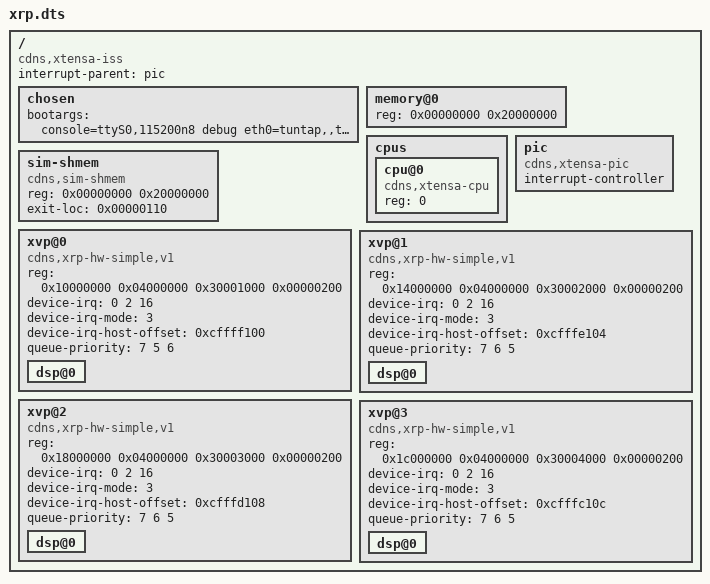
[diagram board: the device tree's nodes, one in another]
/*
 * Copyright (c) 2016 - 2019 Cadence Design Systems Inc.
 *
 * Permission is hereby granted, free of charge, to any person obtaining
 * a copy of this software and associated documentation files (the
 * "Software"), to deal in the Software without restriction, including
 * without limitation the rights to use, copy, modify, merge, publish,
 * distribute, sublicense, and/or sell copies of the Software, and to
 * permit persons to whom the Software is furnished to do so, subject to
 * the following conditions:
 *
 * The above copyright notice and this permission notice shall be included
 * in all copies or substantial portions of the Software.
 *
 * THE SOFTWARE IS PROVIDED "AS IS", WITHOUT WARRANTY OF ANY KIND,
 * EXPRESS OR IMPLIED, INCLUDING BUT NOT LIMITED TO THE WARRANTIES OF
 * MERCHANTABILITY, FITNESS FOR A PARTICULAR PURPOSE AND NONINFRINGEMENT.
 * IN NO EVENT SHALL THE AUTHORS OR COPYRIGHT HOLDERS BE LIABLE FOR ANY
 * CLAIM, DAMAGES OR OTHER LIABILITY, WHETHER IN AN ACTION OF CONTRACT,
 * TORT OR OTHERWISE, ARISING FROM, OUT OF OR IN CONNECTION WITH THE
 * SOFTWARE OR THE USE OR OTHER DEALINGS IN THE SOFTWARE.
 */

/dts-v1/;

/ {
	compatible = "cdns,xtensa-iss";
	#address-cells = <1>;
	#size-cells = <1>;
	interrupt-parent = <&pic>;

	chosen {
		bootargs = "console=ttyS0,115200n8 debug eth0=tuntap,,tap9 root=/dev/simdisk0";
	};

	memory@0 {
		device_type = "memory";
		reg = <0x00000000 0x20000000>;
	};

	cpus {
		#address-cells = <1>;
		#size-cells = <0>;
		cpu@0 {
			compatible = "cdns,xtensa-cpu";
			reg = <0>;
		};
	};

	pic: pic {
		compatible = "cdns,xtensa-pic";
		/* one cell: internal irq number,
		 * two cells: second cell == 0: internal irq number
		 *            second cell == 1: external irq number
		 */
		#interrupt-cells = <2>;
		interrupt-controller;
	};

	sim-shmem {
		compatible = "cdns,sim-shmem";
		reg = <0x00000000 0x20000000>;
		exit-loc = <0x00000110>;
		reg-names = "SharedRAM_L";
	};

	xvp@0 {
		#address-cells = <1>;
		#size-cells = <1>;
		compatible = "cdns,xrp-hw-simple,v1";
		reg = <0x10000000 0x04000000
		       0x30001000 0x00000200>;
		device-irq = <0 2 16>; /* offset, bit#, IRQ# */
		device-irq-mode = <3>;
		device-irq-host-offset = <0xcffff100>;
		queue-priority = <7 5 6>;
		ranges = <0x00000000 0x00000000 0x20000000
			  0xcff80000 0x20000000 0x00040000
			  0xcffc0000 0x20040000 0x00040000
			  0xd0000000 0x20080000 0x00008000
			  0xd0080000 0xd0080000 0x01000000
			  0xe0000000 0xe0000000 0x20000000>;
		dsp@0 {
		};
	};

	xvp@1 {
		#address-cells = <1>;
		#size-cells = <1>;
		compatible = "cdns,xrp-hw-simple,v1";
		reg = <0x14000000 0x04000000
		       0x30002000 0x00000200>;
		device-irq = <0 2 16>; /* offset, bit#, IRQ# */
		device-irq-mode = <3>;
		device-irq-host-offset = <0xcfffe104>;
		queue-priority = <7 6 5>;
		ranges = <0x00000000 0x00000000 0x20000000
			  0xcff80000 0x200c0000 0x00040000
			  0xcffc0000 0x20100000 0x00040000
			  0xd0000000 0x20140000 0x00008000
			  0xd0080000 0xd0080000 0x01000000
			  0xe0000000 0xe0000000 0x20000000>;
		dsp@0 {
		};
	};

	xvp@2 {
		#address-cells = <1>;
		#size-cells = <1>;
		compatible = "cdns,xrp-hw-simple,v1";
		reg = <0x18000000 0x04000000
		       0x30003000 0x00000200>;
		device-irq = <0 2 16>; /* offset, bit#, IRQ# */
		device-irq-mode = <3>;
		device-irq-host-offset = <0xcfffd108>;
		queue-priority = <7 6 5>;
		ranges = <0x00000000 0x00000000 0x20000000
			  0xcff80000 0x20180000 0x00040000
			  0xcffc0000 0x201c0000 0x00040000
			  0xd0000000 0x20200000 0x00008000
			  0xd0080000 0xd0080000 0x01000000
			  0xe0000000 0xe0000000 0x20000000>;
		dsp@0 {
		};
	};

	xvp@3 {
		#address-cells = <1>;
		#size-cells = <1>;
		compatible = "cdns,xrp-hw-simple,v1";
		reg = <0x1c000000 0x04000000
		       0x30004000 0x00000200>;
		device-irq = <0 2 16>; /* offset, bit#, IRQ# */
		device-irq-mode = <3>;
		device-irq-host-offset = <0xcfffc10c>;
		queue-priority = <7 6 5>;
		ranges = <0x00000000 0x00000000 0x20000000
			  0xcff80000 0x20240000 0x00040000
			  0xcffc0000 0x20280000 0x00040000
			  0xd0000000 0x202c0000 0x00008000
			  0xd0080000 0xd0080000 0x01000000
			  0xe0000000 0xe0000000 0x20000000>;
		dsp@0 {
		};
	};
};
